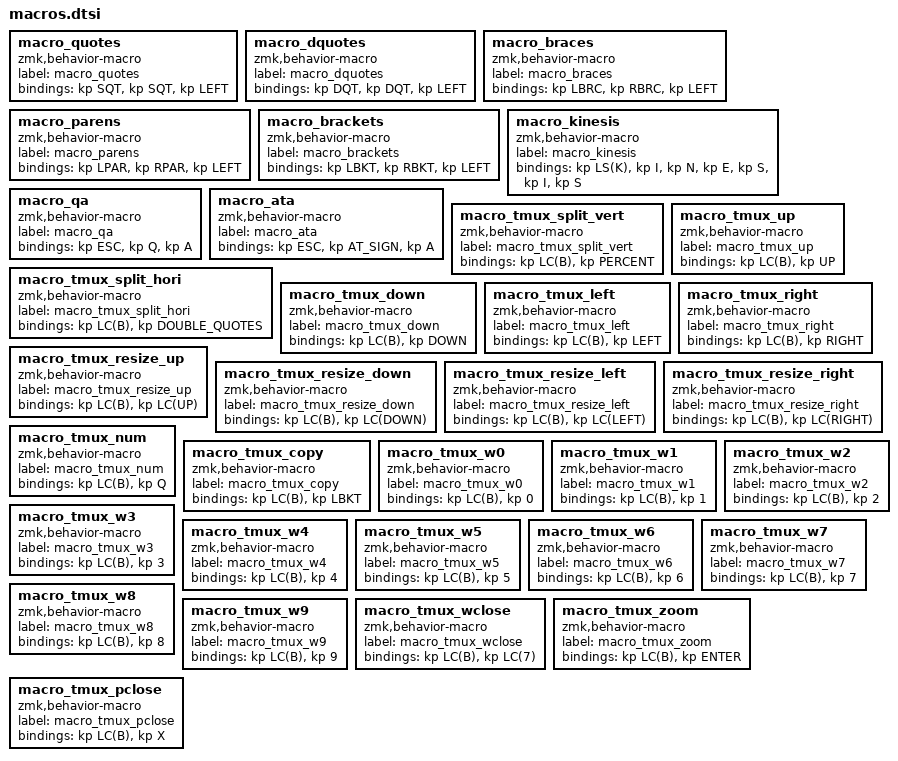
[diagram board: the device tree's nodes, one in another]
macro_quotes: macro_quotes{
compatible = "zmk,behavior-macro";
label = "macro_quotes";
#binding-cells = <0>;
bindings = <&kp SQT>, <&kp SQT>, <&kp LEFT>;
};
macro_dquotes: macro_dquotes{
compatible = "zmk,behavior-macro";
label = "macro_dquotes";
#binding-cells = <0>;
bindings = <&kp DQT>, <&kp DQT>, <&kp LEFT>;
};
macro_braces: macro_braces{
compatible = "zmk,behavior-macro";
label = "macro_braces";
#binding-cells = <0>;
bindings = <&kp LBRC>, <&kp RBRC>, <&kp LEFT>;
};
macro_parens: macro_parens{
compatible = "zmk,behavior-macro";
label = "macro_parens";
#binding-cells = <0>;
bindings = <&kp LPAR>, <&kp RPAR>, <&kp LEFT>;
};
macro_brackets: macro_brackets{
compatible = "zmk,behavior-macro";
label = "macro_brackets";
#binding-cells = <0>;
bindings = <&kp LBKT>, <&kp RBKT>, <&kp LEFT>;
};
macro_kinesis: macro_kinesis{
compatible = "zmk,behavior-macro";
label = "macro_kinesis";
#binding-cells = <0>;
bindings = <&kp LS(K)>, <&kp I>, <&kp N>, <&kp E>, <&kp S>, <&kp I>, <&kp S>;
};
macro_qa: macro_qa{
compatible = "zmk,behavior-macro";
label = "macro_qa";
#binding-cells = <0>;
bindings = <&kp ESC>, <&kp Q>, <&kp A>;
};
macro_ata: macro_ata{
compatible = "zmk,behavior-macro";
label = "macro_ata";
#binding-cells = <0>;
bindings = <&kp ESC>, <&kp AT_SIGN>, <&kp A>;
};
macro_tmux_split_vert: macro_tmux_split_vert{
compatible = "zmk,behavior-macro";
label = "macro_tmux_split_vert";
#binding-cells = <0>;
bindings = <&kp LC(B)>, <&kp PERCENT>;
};
macro_tmux_split_hori: macro_tmux_split_hori{
compatible = "zmk,behavior-macro";
label = "macro_tmux_split_hori";
#binding-cells = <0>;
bindings = <&kp LC(B)>, <&kp DOUBLE_QUOTES>;
};
macro_tmux_up: macro_tmux_up{
compatible = "zmk,behavior-macro";
label = "macro_tmux_up";
#binding-cells = <0>;
bindings = <&kp LC(B)>, <&kp UP>;
};
macro_tmux_down: macro_tmux_down{
compatible = "zmk,behavior-macro";
label = "macro_tmux_down";
#binding-cells = <0>;
bindings = <&kp LC(B)>, <&kp DOWN>;
};
macro_tmux_left: macro_tmux_left{
compatible = "zmk,behavior-macro";
label = "macro_tmux_left";
#binding-cells = <0>;
bindings = <&kp LC(B)>, <&kp LEFT>;
};
macro_tmux_right: macro_tmux_right{
compatible = "zmk,behavior-macro";
label = "macro_tmux_right";
#binding-cells = <0>;
bindings = <&kp LC(B)>, <&kp RIGHT>;
};
macro_tmux_resize_up: macro_tmux_resize_up{
compatible = "zmk,behavior-macro";
label = "macro_tmux_resize_up";
#binding-cells = <0>;
bindings = <&kp LC(B)>, <&kp LC(UP)>;
};
macro_tmux_resize_down: macro_tmux_resize_down{
compatible = "zmk,behavior-macro";
label = "macro_tmux_resize_down";
#binding-cells = <0>;
bindings = <&kp LC(B)>, <&kp LC(DOWN)>;
};
macro_tmux_resize_left: macro_tmux_resize_left{
compatible = "zmk,behavior-macro";
label = "macro_tmux_resize_left";
#binding-cells = <0>;
bindings = <&kp LC(B)>, <&kp LC(LEFT)>;
};
macro_tmux_resize_right: macro_tmux_resize_right{
compatible = "zmk,behavior-macro";
label = "macro_tmux_resize_right";
#binding-cells = <0>;
bindings = <&kp LC(B)>, <&kp LC(RIGHT)>;
};
macro_tmux_num: macro_tmux_num{
compatible = "zmk,behavior-macro";
label = "macro_tmux_num";
#binding-cells = <0>;
bindings = <&kp LC(B)>, <&kp Q>;
};
macro_tmux_copy: macro_tmux_copy{
compatible = "zmk,behavior-macro";
label = "macro_tmux_copy";
#binding-cells = <0>;
bindings = <&kp LC(B)>, <&kp LBKT>;
};
macro_tmux_w0: macro_tmux_w0{
compatible = "zmk,behavior-macro";
label = "macro_tmux_w0";
#binding-cells = <0>;
bindings = <&kp LC(B)>, <&kp 0>;
};
macro_tmux_w1: macro_tmux_w1{
compatible = "zmk,behavior-macro";
label = "macro_tmux_w1";
#binding-cells = <0>;
bindings = <&kp LC(B)>, <&kp 1>;
};
macro_tmux_w2: macro_tmux_w2{
compatible = "zmk,behavior-macro";
label = "macro_tmux_w2";
#binding-cells = <0>;
bindings = <&kp LC(B)>, <&kp 2>;
};
macro_tmux_w3: macro_tmux_w3{
compatible = "zmk,behavior-macro";
label = "macro_tmux_w3";
#binding-cells = <0>;
bindings = <&kp LC(B)>, <&kp 3>;
};
macro_tmux_w4: macro_tmux_w4{
compatible = "zmk,behavior-macro";
label = "macro_tmux_w4";
#binding-cells = <0>;
bindings = <&kp LC(B)>, <&kp 4>;
};
macro_tmux_w5: macro_tmux_w5{
compatible = "zmk,behavior-macro";
label = "macro_tmux_w5";
#binding-cells = <0>;
bindings = <&kp LC(B)>, <&kp 5>;
};
macro_tmux_w6: macro_tmux_w6{
compatible = "zmk,behavior-macro";
label = "macro_tmux_w6";
#binding-cells = <0>;
bindings = <&kp LC(B)>, <&kp 6>;
};
macro_tmux_w7: macro_tmux_w7{
compatible = "zmk,behavior-macro";
label = "macro_tmux_w7";
#binding-cells = <0>;
bindings = <&kp LC(B)>, <&kp 7>;
};
macro_tmux_w8: macro_tmux_w8{
compatible = "zmk,behavior-macro";
label = "macro_tmux_w8";
#binding-cells = <0>;
bindings = <&kp LC(B)>, <&kp 8>;
};
macro_tmux_w9: macro_tmux_w9{
compatible = "zmk,behavior-macro";
label = "macro_tmux_w9";
#binding-cells = <0>;
bindings = <&kp LC(B)>, <&kp 9>;
};
macro_tmux_wclose: macro_tmux_wclose{
compatible = "zmk,behavior-macro";
label = "macro_tmux_wclose";
#binding-cells = <0>;
bindings = <&kp LC(B)>, <&kp LC(7)>;
};
macro_tmux_zoom: macro_tmux_zoom{
compatible = "zmk,behavior-macro";
label = "macro_tmux_zoom";
#binding-cells = <0>;
bindings = <&kp LC(B)>, <&kp ENTER>;
};
macro_tmux_pclose: macro_tmux_pclose{
compatible = "zmk,behavior-macro";
label = "macro_tmux_pclose";
#binding-cells = <0>;
bindings = <&kp LC(B)>, <&kp X>;
};
